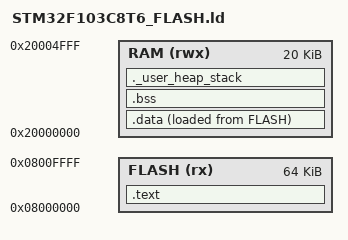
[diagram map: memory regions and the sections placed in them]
ENTRY(Reset_Handler)

_stack_size = 0x200;

MEMORY
{
  FLASH (rx) : ORIGIN = 0x08000000, LENGTH = 64K
  RAM (rwx) : ORIGIN = 0x20000000, LENGTH = 20K
}

SECTIONS
{
  .text :
  {
    . = ALIGN(4);
    KEEP(*(.isr_vector))
    *(.text)
    *(.text*)
    *(.rodata)
    *(.rodata*)
    . = ALIGN(4);
    _etext = .;
  } > FLASH

  .data :
  {
    _sdata = .;
    *(.data)
    *(.data*)
    . = ALIGN(4);
    _edata = .;
  } > RAM AT > FLASH

  _sidata = LOADADDR(.data);

  .bss :
  {
    . = ALIGN(4);
    _sbss = .;
    *(.bss)
    *(.bss*)
    *(COMMON)
    . = ALIGN(4);
    _ebss = .;
  } > RAM

  ._user_heap_stack :
  {
    . = ALIGN(8);
    _end = .;
    . = . + _stack_size;
    . = ALIGN(8);
    _estack = .;
  } > RAM

  /DISCARD/ :
  {
    libc.a (*)
    libm.a (*)
    libgcc.a (*)
  }
}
